# AE402FA0D5597BE0_CM55_HE_View register map
Vendor: Alif Semiconductor; Series: E4; File version: 1.0
CPU: CM55 r1p0, selectable endian, MPU, FPU, double-precision FPU, DSP, VTOR, 8 interrupt priority bits, 1 SAU regions
Registers are 32-bit, read-write, reset 0x0 unless marked. A register's access mark holds for its fields unless they carry their own. Offsets are from the block's base; [hi:lo] are bit positions; {n}, {i} and the like mark numbered series; 'fields as' and 'values as' point back to an identical list.

## ISP (part 1 of 2)
Base 0x49046000
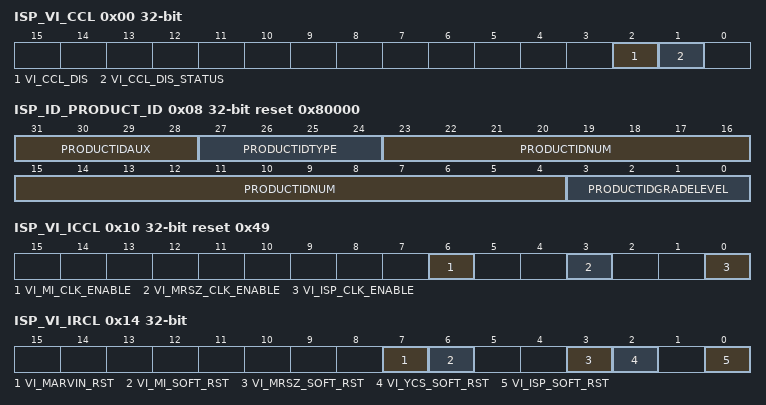
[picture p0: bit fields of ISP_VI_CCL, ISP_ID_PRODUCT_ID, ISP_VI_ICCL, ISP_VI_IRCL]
0x00 ISP_VI_CCL
  [2] VI_CCL_DIS — Clock Control Logic disable
    0=Processing/cfg-clocks for all sub modules enabled; 1=Processing/cfg-clocks for all sub modules disabled without access to ID and ISP_VI_CCL register
  [1] VI_CCL_DIS_STATUS — Status of ISP_vi_ccl[2] bit (copy of ISP_vi_ccl[2])
0x04 ISP_ID_CUSTOM_ID ro reset 0x50000091
  [31:0] ISP_ID_CUSTOM_ID — Shows Proejct ID, Each Project maps to a Unique ProjectID 0x83:
    128=Project-0; 129=Project-1; 130=Project-2
0x08 ISP_ID_PRODUCT_ID ro reset 0x80000
  [31:28] PRODUCTIDAUX — Product Aux
  [27:24] PRODUCTIDTYPE — Following is a Example for this 4bit field (GPU/VIP Using) , You can plan the values accordling to ISP 's Product RoadMap Product Type
    0=ISP Only; 1=DW Only; 2=VSE Only; 3=ISP + DW100; 4=ISP + DW100 + VSE; 5=ISP + DW200
  [23:4] PRODUCTIDNUM — Shows Product Number, Example: ISP8000L,ProductIDNum=0x08000 DW100,ProductIDNum=0x00100 DW200,ProductIDNum=0x00200
  [3:0] PRODUCTIDGRADELEVEL — Product GradeLevel
    0=None-no extra letter on the product name; 1=N (Nano); 2=L (Lite); 3=D,Dual; 4=N-D, Nano-Dual; 5=L-D, Lite-Dual
0x0C ISP_ID_CHIP_ID ro reset 0x8000
  [31:0] ISP_ID_CHIP_ID — Shows ChipID numbers ISPNano Series,ChipID=0x8000 ISP8000L Series,ChipID=0x8000 ISP8000 Series,ChipID=0x8000 DW100,ChipID=0x0100 DW200,ChipID=0x0200
0x10 ISP_VI_ICCL reset 0x49
  [all] fields
    0=Power safe; 1=Processing mode
  [6] VI_MI_CLK_ENABLE — Memory interface clock enable
  [3] VI_MRSZ_CLK_ENABLE — main resize clock enable
  [0] VI_ISP_CLK_ENABLE — ISP processing clock enable
0x14 ISP_VI_IRCL
  [all] fields
    0=Processing mode; 1=Reset state
  [7] VI_MARVIN_RST — Hardware reset of entire image signal processor
  [6] VI_MI_SOFT_RST — Memory interface software reset
  [3] VI_MRSZ_SOFT_RST — Main-picture resize software reset
  [2] VI_YCS_SOFT_RST — Y/C splitter software reset
  [0] VI_ISP_SOFT_RST — ISP software reset
0x20 ISP_ID_ECO_ID ro
  [31:0] ISP_ID_ECO_ID — Formal release is 0x0 The 1st ECO release is 0x1 The 2nd ECO release is 0x2
0x24 ISP_ID_CHIP_REVISION ro reset 0x5000
  [31:0] ISP_ID_CHIP_REVISION — Shows Tag Number Example: Tag=isp8000_1_2_1_rc3z Then,ChipRevision=0x0000_1213
0x28 ISP_ID_PATCH_REVISION ro reset 0x7
  [31:0] ISP_ID_PATCH_REVISION — Shows the last letter of a Tag Example: Tag=isp8000_1_2_1_rc3z Then,PatchRevision=8'd26 'a' map to 8'd1 'b' map to 8'd2 'z' map to 8'd26
0x2C ISP_ID_CHIP_DATE ro
  [31:0] ISP_ID_CHIP_DATE — Shows Date Value,such as 32'h20191120
0x30 ISP_ID_CHIP_TIME ro reset 0x1800
  [31:0] ISP_ID_CHIP_TIME — Shows Time Value,such as 32'h18365500
0x34 ISP_VI_ID_RSV0 ro reset 0xA100
  [31:0] MARVIN_ID_RSV0 — reserved id
0x38 ISP_VI_ID_RSV1 ro reset 0xA1
  [31:0] MARVIN_ID_RSV1 — reserved id
0x3C ISP_VI_ID_RSV2 ro reset 0xA2
  [31:0] MARVIN_ID_RSV2 — reserved id
0x40 ISP_VI_ID_RSV3 ro reset 0xA3
  [31:0] MARVIN_ID_RSV3 — reserved id
0x44 ISP_VI_ID_RSV4 ro reset 0xA4
  [31:0] MARVIN_ID_RSV4 — reserved id
0x48 ISP_VI_ID_RSV5 ro reset 0xA5
  [31:0] MARVIN_ID_RSV5 — reserved id
0x4C ISP_VI_ID_RSV6 ro reset 0xA6
  [31:0] MARVIN_ID_RSV6 — reserved id
0x50 ISP_VI_ID_RSV7 ro reset 0xA7
  [31:0] MARVIN_ID_RSV7 — reserved id
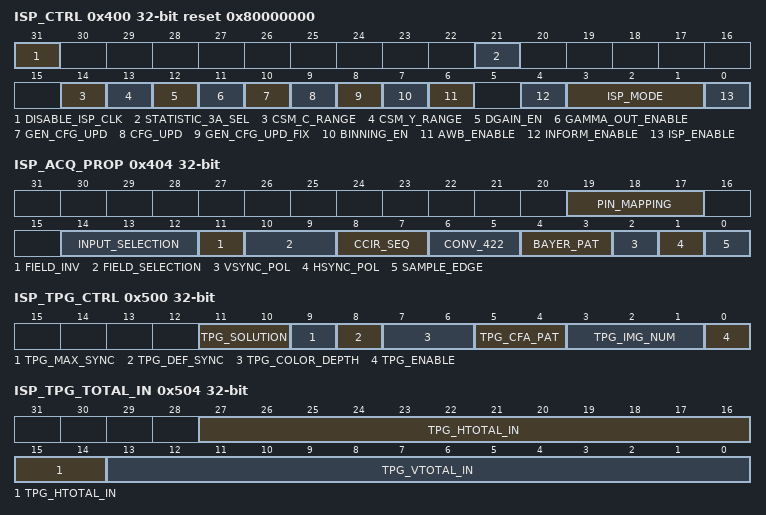
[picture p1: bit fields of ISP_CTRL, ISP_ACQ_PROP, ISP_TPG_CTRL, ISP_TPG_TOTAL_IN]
0x400 ISP_CTRL reset 0x80000000
  [31] DISABLE_ISP_CLK
    1=Enable ISP clock of SRAM. 0:disable isp clock of sram
  [21] STATISTIC_3A_SEL
    1=Select demosaic output 0: Select cc output
  [14] CSM_C_RANGE — Color Space Matrix chrominance clipping range for ISP output Numbers in brackets are for 8 bit resolution. This bit also configures the YCbCr sequence align block accordingly.
    0=CbCr range 64..960 (16..240) according to ITU-R BT.601 standard; 1=Full UV range 0..1023 (0..255)
  [13] CSM_Y_RANGE — Color Space Matrix luminance clipping range for ISP output Numbers in brackets are for 8 bit resolution. This bit also configures the YCbCr sequence align block accordingly.
    0=Y range 64..940 (16..235) according to ITU-R BT.601 standard; 1=Full Y range 0..1023 (0..255)
  [12] DGAIN_EN — digital gain enable
  [11] GAMMA_OUT_ENABLE — Gamma ON/OFF
  [10] GEN_CFG_UPD
    1=Generate frame synchronous configuration signal at the output of ISP for shadow registers of the following processing modules, write only
  [9] CFG_UPD
    1=Immediately configure (update) shadow registers, write only
  [8] GEN_CFG_UPD_FIX
    1=Make gen_cfg_upd a level signal, effect since then; 0=Gen_cfg_upd is a pulse signal, only effect for current frame
  [7] BINNING_EN — binning enable
  [6] AWB_ENABLE — Auto white balance ON/OFF
  [4] INFORM_ENABLE — input formatter The ISP input formatter is enabled or disabled by this bit immediately, But always starts or stops acquisition frame synchronously.
    0=Disabled; 1=Enabled
  [3:1] ISP_MODE — 000 - RAW picture with BT.601 sync (ISP bypass) 001 - ITU-R BT.656 (YUV with embedded sync) 010 - ITU-R BT.601 (YUV input with H and Vsync signals) 011 - Bayer RGB processing with H and Vsync signals 100 - data mode (ISP bypass, sync signals interpreted as data enable) 101 - Bayer RGB processing with BT.656 synchronization 110 - RAW picture with ITU-R BT.656 synchronization (ISP bypass) 111 - monochrome Side effect: If RAW, BT.601, BT.656, or data mode is selected, the clock of the ISP SRAMs (ISP line buffer, Lens Shading, Bad Pixel) is switched off. Only in Bayer RGB mode the clock to the SRAMs is enabled. This further reduces power consumption.
  [0] ISP_ENABLE — ISP data output Controls output formatter frame synchronously, if isp_gen_cfg_upd is Used to activate this bit. For immediate update isp_cfg_upd must be used.
    0=Disabled; 1=Enabled
0x404 ISP_ACQ_PROP
  [19:17] PIN_MAPPING — Bit mapping from LSB to MSB: 000 - normal 12-bit external Interface 001 - mapping Low 10 bit to High 10 bits, append 2 zeroes as LSBs 010 - mapping Low 8 bit to High 8 bits, append 4 zeroes as LSBs 011 - mapping Middle 8 bit to High 8 bits, append 4 zeroes as LSBs 100...111 - Reserved (from March 2018)
  [14:12] INPUT_SELECTION — 12bit/10bit/8bit input select modes 000- 12Bit external Interface 001- 10Bit Interface, append 2 zeroes as LSBs 010- 10Bit Interface, append 2 MSBs as LSBs 011- 8Bit Interface, append 4 zeroes as LSBs 100- 8Bit Interface, append 4 MSBs as LSBs 101...111 reserved
  [11] FIELD_INV
    0=Do not swap odd and even fields; 1=Swap odd and even fields
  [10:9] FIELD_SELECTION — 00- sample all fields (don't care about fields) 01- sample only even fields 10- sample only odd fields 11- reserved
  [8:7] CCIR_SEQ — 00- YCbYCr 01- YCrYCb 10- CbYCrY 11- CrYCbY
  [6:5] CONV_422 — 00- cosited color subsampling Y0Cb0Cr0 - Y1 01- interleaved color subsampling Y0Cb0 - Y1Cr1 (not recommended) 10- non-cosited color subsampling Y0Cb(0+1)/2 - Y1Cr(0+1)/2 11- reserved
  [4:3] BAYER_PAT — Color components from sensor, starting with top left position in sampled frame (reprogram with ISP_ACQ_H_OFFS, ISP_ACQ_V_OFFS) 00- first line: RGRG..., second line: GBGB..., etc. 01- first line: GRGR..., second line: BGBG..., etc. 10- first line: GBGB..., second line: RGRG..., etc. 11- first line: BGBG..., second line: GRGR..., etc. This configuration applies for the black level area after cropping by the input formatter.
  [2] VSYNC_POL — Vertical sync polarity
    0=High active; 1=Low active
  [1] HSYNC_POL — Horizontal sync polarity
    0=High active; 1=Low active
  [0] SAMPLE_EDGE — 0- negative edge sampling 1- positive edge sampling
0x408 ISP_ACQ_H_OFFS
  [14:0] ACQ_H_OFFS — Horizontal sample offset in 8-bit samples (YUV: 4 samples = 2 pixels)
0x40C ISP_ACQ_V_OFFS
  [13:0] ACQ_V_OFFS — Vertical sample offset in lines
0x410 ISP_ACQ_H_SIZE reset 0x1000
  [14:0] ACQ_H_SIZE — Horizontal sample size in 12-bit samples YUV input: 2 samples = 1 pixel, else 1 sample = 1 pixel So in YUV mode ACQ_H_SIZE must be twice as large as horizontal image size. Horizontal image size must always be even except in raw picture mode if an odd size is programmed, the value will be truncated to an even size.
0x414 ISP_ACQ_V_SIZE reset 0xC00
  [13:0] ACQ_V_SIZE — Vertical sample size in lines
0x500 ISP_TPG_CTRL
  [11:10] TPG_SOLUTION
    0=Val_0b00 (1080P (1920x1080)); 1=Val_0b01 (720P (1280x720)); 2=Val_0b10 (4K (3840x2160)); 3=Val_0b11 (User defined resolution and timing)
  [9] TPG_MAX_SYNC — Set to 1 to use VS/VDE and HS/HDE same behavior
  [8] TPG_DEF_SYNC — Set to 1 to select the default sync output
  [7:6] TPG_COLOR_DEPTH — Test Pattern Color Depth
    0=Val_0b00 (8-bit); 1=Val_0b01 (10-bit); 2=Val_0b10 (12-bit (pix_width))
  [5:4] TPG_CFA_PAT — Bayer pattern:
    0=Val_0b00 (RGGB); 1=Val_0b01 (GRBG); 2=Val_0b10 (GBRB); 3=Val_0b11 (BGGR)
  [3:1] TPG_IMG_NUM — Test Pattern Generator Image index Others: Reserved
    0=Val_0b000 (3x3 color block); 1=Val_0b001 (Color bar); 2=Val_0b010 (Gray Bar); 3=Val_0b011 (Highlighted grid); 4=Val_0b100 (Random Generator)
  [0] TPG_ENABLE — Enable/Disable Test Pattern Generator
    0=Disable the TPG; 1=Enable the TPG
0x504 ISP_TPG_TOTAL_IN
  [27:14] TPG_HTOTAL_IN — The total clock of vertical
  [13:0] TPG_VTOTAL_IN — The total clock of horizontal
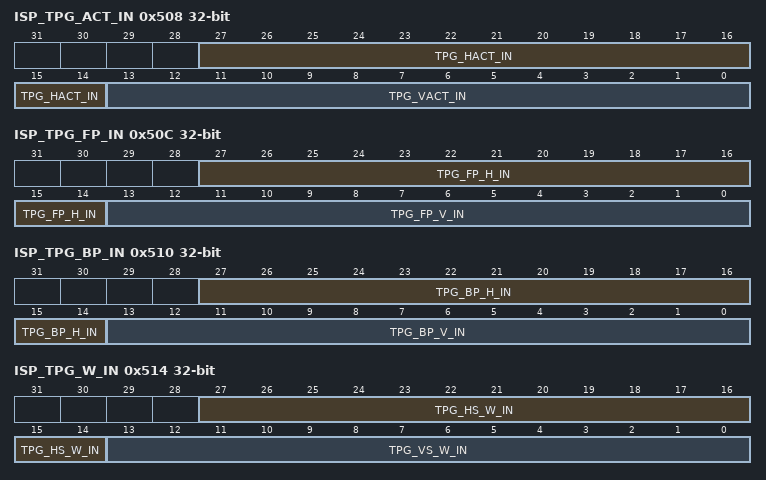
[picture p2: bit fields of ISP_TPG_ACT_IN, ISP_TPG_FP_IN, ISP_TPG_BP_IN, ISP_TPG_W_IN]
0x508 ISP_TPG_ACT_IN
  [27:14] TPG_HACT_IN — The total clock of horizontal
  [13:0] TPG_VACT_IN — The available clock of vertical
0x50C ISP_TPG_FP_IN
  [27:14] TPG_FP_H_IN — The first valid of hs
  [13:0] TPG_FP_V_IN — The first valid of vs
0x510 ISP_TPG_BP_IN
  [27:14] TPG_BP_H_IN — The distance between positive edge of vs with positive edge of hde
  [13:0] TPG_BP_V_IN — The distance between positive edge of vs with positive edge of vde
0x514 ISP_TPG_W_IN
  [27:14] TPG_HS_W_IN — Available clk of hs
  [13:0] TPG_VS_W_IN — Available clk of vs
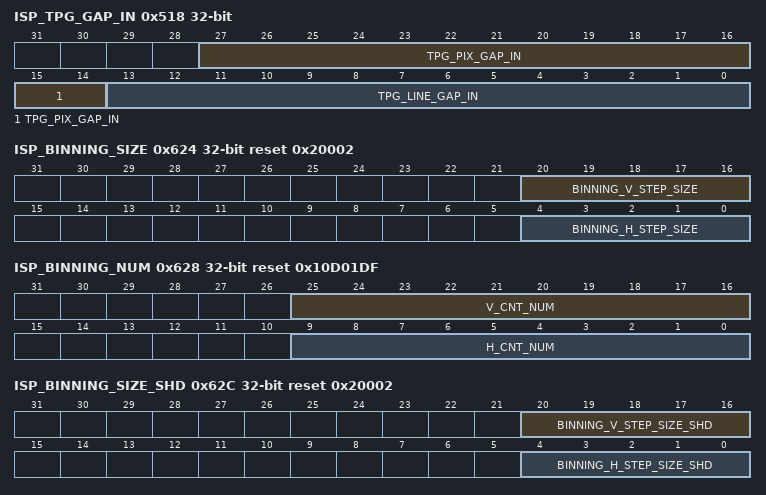
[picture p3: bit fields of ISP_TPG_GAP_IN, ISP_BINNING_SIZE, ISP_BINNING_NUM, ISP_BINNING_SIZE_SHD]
0x518 ISP_TPG_GAP_IN
  [27:14] TPG_PIX_GAP_IN — The width of sub_picture
  [13:0] TPG_LINE_GAP_IN — The height of sub_picture
0x51C ISP_TPG_GAP_STD_IN
  [13:0] TPG_PIX_GAP_STD_IN — The gap of sub_picture
0x520 ISP_TPG_RANDOM_SEED
  [31:0] TPG_RANDOM_SEED — Random seed
0x524 ISP_TPG_FRAME_NUM
  [15:0] TPG_FRAME_NUM — Other: when the frame_cnt &lt = frame_num, the output is valid
    0=all of the frame output is valid
0x600 ISP_FRAME_RATE
  [5:0] FRAME_RATE — Frame rate: N: 1/(N+1) of the original frame rate N: 1/(N=1) of the original frame rate
    0=Original frame rate; {v}=1/{v+1} of the original frame rate (v=1..6)
0x604 ISP_OUT_H_OFFS
  [13:0] OUT_H_OFFS — Horizontal pic offset in lines
0x608 ISP_OUT_V_OFFS
  [13:0] OUT_V_OFFS — Vertical pic offset in lines
0x60C ISP_OUT_H_SIZE reset 0x280
  [14:0] OUT_H_SIZE — Horizontal picture size in pixel if ISP_MODE is set to: 001-(ITU-R BT.656 YUV), 010-( ITU-R BT.601 YUV), 011-( ITU-R BT.601 Bayer RGB), 101-( ITU-R BT.656 Bayer RGB) Only even numbers are accepted, because complete quadruples of YUYV(YCbYCr) are needed for the 422 output. If an odd size is programmed, the value will be truncated to an even size.
0x610 ISP_OUT_V_SIZE reset 0x1E0
  [13:0] OUT_V_SIZE — Vertical picture size in lines
0x614 ISP_OUT_H_OFFS_SHD ro
  [13:0] OUT_H_OFFS_SHD — Current horizontal picture offset in lines
0x618 ISP_OUT_V_OFFS_SHD ro
  [13:0] OUT_V_OFFS_SHD — Current vertical picture offset in lines
0x61C ISP_OUT_H_SIZE_SHD ro
  [14:0] OUT_H_SIZE_SHD — Current horizontal picture size in pixels.
0x620 ISP_OUT_V_SIZE_SHD ro
  [13:0] OUT_V_SIZE_SHD — Current vertical picture size in lines.
0x624 ISP_BINNING_SIZE reset 0x20002
  [20:16] BINNING_V_STEP_SIZE — vertical step size ,if(binning_en) value&gt =1 and must be even
  [4:0] BINNING_H_STEP_SIZE — Horizontal step size ,if(binning_en) value&gt =1 and must be even
0x628 ISP_BINNING_NUM reset 0x10D01DF
  [25:16] V_CNT_NUM — vertical counter num accodring to vsize and v_step_size ,equal to ceil[vsize/(v_step_size*2)]-1
  [9:0] H_CNT_NUM — horizontal counter num accodring to hsize and h_step_size,ceil[hsize/(h_step_size*2)]-1
0x62C ISP_BINNING_SIZE_SHD ro reset 0x20002
  [20:16] BINNING_V_STEP_SIZE_SHD — vertical step size ,if(binning_en) value&gt =1 and must be even
  [4:0] BINNING_H_STEP_SIZE_SHD — Horizontal step size ,if(binning_en) value&gt =1 and must be even
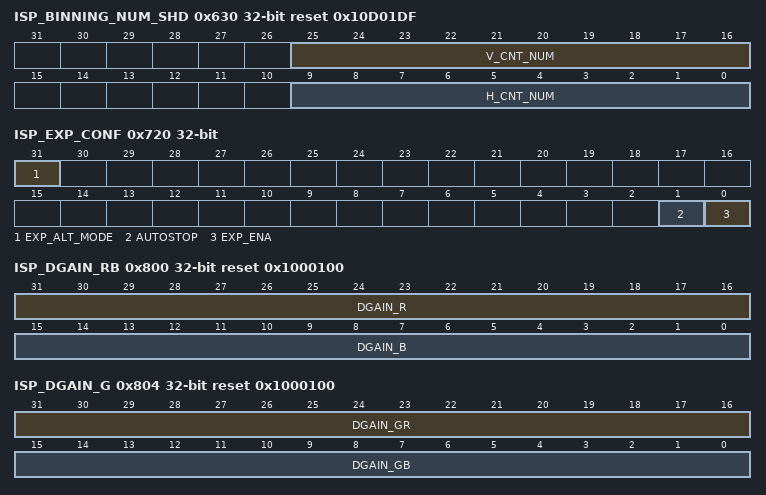
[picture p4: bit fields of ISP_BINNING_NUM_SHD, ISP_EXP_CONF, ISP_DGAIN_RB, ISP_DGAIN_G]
0x630 ISP_BINNING_NUM_SHD ro reset 0x10D01DF
  fields as ISP_BINNING_NUM
0x700 ISP_BLS_CTRL
  [0] BLS_EN
    1=Black level subtraction is enabled; 0=Bypass the black level processing
0x704 ISP_BLS_A_FIXED
  [12:0] BLS_A_FIXED — Fixed black level for A pixels-signed, two's complement Valid range from -4096 to +4095, A positive value will be subtracted from the pixel values
0x708 ISP_BLS_B_FIXED
  [12:0] BLS_B_FIXED — Fixed black level for B pixels-signed, two's complement Valid range from -4096 to +4095, A positive value will be subtracted from the pixel values
0x70C ISP_BLS_C_FIXED
  [12:0] BLS_C_FIXED — Fixed black level for C pixels-signed, two's complement Valid range from -4096 to +4095, A positive value will be subtracted from the pixel values
0x710 ISP_BLS_D_FIXED
  [12:0] BLS_D_FIXED — Fixed black level for D pixels-signed, two's complement Valid range from -4096 to +4095, A positive value will be subtracted from the pixel values
0x720 ISP_EXP_CONF
  [31] EXP_ALT_MODE
    0=Luminance calculation according to Y=16+0.25R+0.5G+0.1094B; 1=Luminance calculation according to Y=(R+G+B) x 0.332
  [1] AUTOSTOP
    0=Continuous measurement; 1=Stop measuring after a complete frame
  [0] EXP_ENA
    1=Start measuring a frame. If autostop is set to 1, the exposure block will reset this bit and halt after completing one frame.
0x724 ISP_EXP_H_OFFSET
  [12:0] EXP_H_OFFSET — Horizontal offset of first block in pixels.
0x728 ISP_EXP_V_OFFSET
  [12:0] EXP_V_OFFSET — Vertical offset of first block in pixels.
0x72C ISP_EXP_H_SIZE
  [10:0] EXP_H_SIZE — Horizontal size of one block in pixels.
0x730 ISP_EXP_V_SIZE
  [10:0] EXP_V_SIZE — Vertical size of one block in pixels (must be a multiple of 2). Note: The vertical size must be set in a way that after the last measurement window, At least two lines of the image will follow. I
{0x734+0x14*i} ISP_EXP_MEAN_{i:02} ro (i=0..4)
  [7:0] EXP_MEAN_{i:02} — Mean luminance value of block {i:02} (x,y)
{0x670+0x14*i} ISP_EXP_MEAN_{i} ro (i=10..14)
  [7:0] EXP_MEAN_{i} — Mean luminance value of block {i} (x,y)
{0x5AC+0x14*i} ISP_EXP_MEAN_{i} ro (i=20..24)
  [7:0] EXP_MEAN_{i} — Mean luminance value of block {i} (x,y)
{0x4E8+0x14*i} ISP_EXP_MEAN_{i} ro (i=30..34)
  [7:0] EXP_MEAN_{i} — Mean luminance value of block {i} (x,y)
{0x424+0x14*i} ISP_EXP_MEAN_{i} ro (i=40..44)
  [7:0] EXP_MEAN_{i} — Mean luminance value of block {i} (x,y)
0x800 ISP_DGAIN_RB reset 0x1000100
  [31:16] DGAIN_R — digital gain of red channel
  [15:0] DGAIN_B — digital gain of blue channel
0x804 ISP_DGAIN_G reset 0x1000100
  [31:16] DGAIN_GR — digital gain of red line green channel
  [15:0] DGAIN_GB — digital gain of blue line green channel
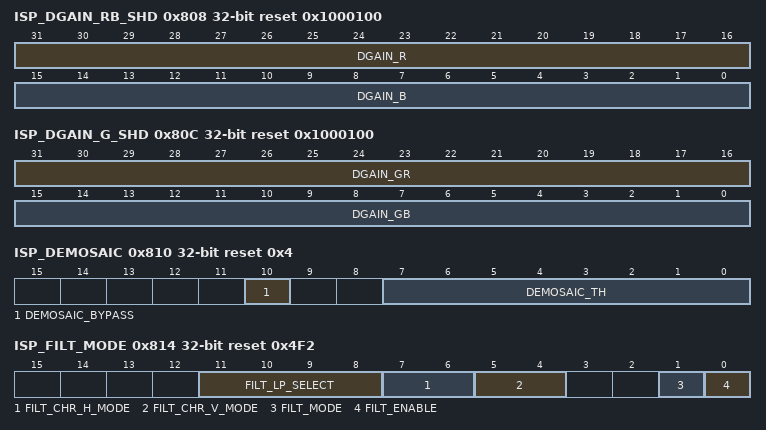
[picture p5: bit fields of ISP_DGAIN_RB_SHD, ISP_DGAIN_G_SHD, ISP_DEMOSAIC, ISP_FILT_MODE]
0x808 ISP_DGAIN_RB_SHD ro reset 0x1000100
  fields as ISP_DGAIN_RB
0x80C ISP_DGAIN_G_SHD ro reset 0x1000100
  fields as ISP_DGAIN_G
0x810 ISP_DEMOSAIC reset 0x4
  [10] DEMOSAIC_BYPASS — White input data
    0=Normal operation for RGB Bayer Pattern input; 1=Demosaicing bypass for Black&amp
  [7:0] DEMOSAIC_TH — Threshold for Bayer demosaicing texture detection. This value shifted left 4bit is compared with the difference of the vertical and horizontal 12Bit wide texture indicators, to decide if the vertical or horizontal texture flag must be set.
    0=Maximum edge sensitivity; 255=no texture detection
0x814 ISP_FILT_MODE reset 0x4F2
  [11:8] FILT_LP_SELECT — Green filter stage 1 select (Valid range: 0x0...0x8):
    0=Maximum blurring . . .; 4=Default; 7=minimum blurring; 8=filter stage1 bypass
  [7:6] FILT_CHR_H_MODE — Chroma filter horizontal mode:
    0=Val_0b00 (Horizontal chroma filter bypass); 1=Val_0b01 (Horizontal chroma filter 1 static mask = [10 12 10]); 2=Val_0b10 (Horizontal chroma filter 2 (dynamic blur1)); 3=Val_0b11 (Horizontal chroma filter 3 (dynamic blur2) (Default))
  [5:4] FILT_CHR_V_MODE — Chroma filter vertical mode:
    0=Val_0b00 (Vertical chroma filter bypass); 1=Val_0b01 (Vertical chroma filter 1 static [8 16 8]); 2=Val_0b10 (Vertical chroma filter 2 static [10 12 10]); 3=Val_0b11 (Vertical chroma filter 3 static [12 8 12] (Default))
  [1] FILT_MODE
    0=Green filter static mode (active filter factor = FILT_FAC_MID); 1=Dynamic noise reduction/sharpen (Default)
  [0] FILT_ENABLE
    1=Enable filter; 0=Bypass filter (Default)
0x818 ISP_FILT_THRES_BL0 reset 0xD
  [9:0] FILT_THRES_BL0 — If filt_thresh_bl1 &lt sum_grad &lt filt_thresh_bl0 then filt_fac_bl0 is selected Note: sum_grad is calculated by the texture detection unit as the sum of horizontal and vertical gradients
0x81C ISP_FILT_THRES_BL1 reset 0x5
  [9:0] FILT_THRES_BL1 — If sum_grad &lt filt_thresh_bl1 then filt_fac_bl1 is selected Note: sum_grad is calculated by the texture detection unit as the sum of horizontal and vertical gradients
0x820 ISP_FILT_THRES_SH0 reset 0x1A
  [9:0] FILT_THRES_SH0 — If filt_thresh_sh1 &lt sum_grad &lt filt_thresh_sh0 then filt_fac_bl0 is selected Note: sum_grad is calculated by the texture detection unit as the sum of horizontal and vertical gradients
0x824 ISP_FILT_THRES_SH1 reset 0x2C
  [9:0] FILT_THRES_SH1 — If sum_grad &lt filt_thresh_sh1 then filt_fac_bl1 is selected Note: sum_grad is calculated by the texture detection unit as the sum of horizontal and vertical gradients
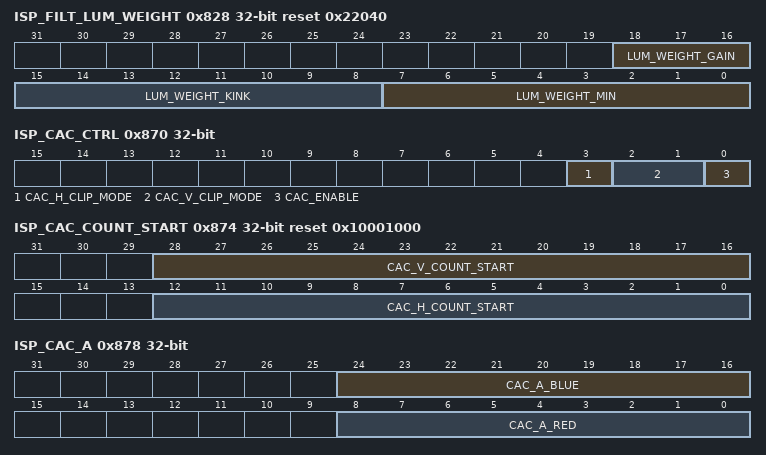
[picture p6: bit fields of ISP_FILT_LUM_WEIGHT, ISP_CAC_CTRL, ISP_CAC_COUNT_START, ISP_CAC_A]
0x828 ISP_FILT_LUM_WEIGHT reset 0x22040
  [18:16] LUM_WEIGHT_GAIN — Gain select of luminance weight function
  [15:8] LUM_WEIGHT_KINK — Kink position of luminance weight function
  [7:0] LUM_WEIGHT_MIN — Minimum value of luminance weight function
0x82C ISP_FILT_FAC_SH1 reset 0x10
  [5:0] FILT_FAC_SH1 — Filter factor for sharp1 level
0x830 ISP_FILT_FAC_SH0 reset 0xC
  [5:0] FILT_FAC_SH0 — Filter factor for sharp0 level
0x834 ISP_FILT_FAC_MID reset 0xA
  [5:0] FILT_FAC_MID — Filter factor for mid level and for static filter mode
0x838 ISP_FILT_FAC_BL0 reset 0x6
  [5:0] FILT_FAC_BL0 — Filter factor for blur 0 level
0x83C ISP_FILT_FAC_BL1 reset 0x2
  [5:0] FILT_FAC_BL1 — Filter factor for blur 1 level (max blur)
0x870 ISP_CAC_CTRL
  [3] CAC_H_CLIP_MODE — Defines the maximum red/blue pixel shift in horizontal direction At pixel positions, that require a larger displacement, the maximum shift value is used instead (vector clipping)
    0=Set horizontal vector clipping to +/-4 pixel displacement (Default); 1=Set horizontal vector clipping to +/-4 or +/-5 pixel displacement depending on pixel position inside the Bayer raster (dynamic switching between +/-4 and +/-5)
  [2:1] CAC_V_CLIP_MODE — Defines the maximum red/blue pixel shift in vertical direction fix filter_enable (Default) dynamic filter_enable for chroma low pass filter
    0=Val_0b00 (Set vertical vector clipping to +/-2 pixel); 1=Val_0b01 (Set vertical vector clipping to +/-3 pixel); 2=Val_0b10 (Set vertical vector clipping +/-3 or +/-4 pixel displacement depending on pixel position inside the Bayer raster (dynamic switching between +/-3 and +/-4))
  [0] CAC_ENABLE
    0=Chromatic aberration correction off; 1=Chromatic aberration correction on
0x874 ISP_CAC_COUNT_START reset 0x10001000
  [28:16] CAC_V_COUNT_START — 12 bit v_count preload value (range 4095 ... 1) of the vertical CAC line counter. Before frame start v_count has to be preloaded with (v_size/2 + v_center_offset), with v_size the image height and v_center_offset the vertical distance between image center and optical center. After frame start the v_count decrements with every line until a value of zero is reached for the line in the optical center. Than the v_sign bit toggles and the v_counter decrements with every line until end of frame.
  [12:0] CAC_H_COUNT_START — 12 bit h_count preload value (range 4095 .. 1) of the horizontal CAC pixel counter. Before line start h_count has to be preloaded with (h_size/2 + h_center_offset), with h_size the image width and h_center_offset the horizontal distance between image center and optical center. After line start the h_count decrements with every pixel until a value of zero is reached for the column in the optical center. Than the h_sign bit toggles and the h_counter increments with every pixel until end of line.
0x878 ISP_CAC_A
  [24:16] CAC_A_BLUE — Parameter A_Blue for radial blue shift calculation, according to (A_Blue * r + B_Blue * r^2 + C_Blue * r^3). It is a 9 bit twos complement integer with 4 fractional digits value and value range from -16 up to 15.9375.
  [8:0] CAC_A_RED — Parameter A_Red for radial red shift calculation, according to (A_Red * r + B_Red * r^2 + C_Red * r^3). It is a 9 bit twos complement integer with 4 fractional digits value and value range from -16 up to 15.9375.
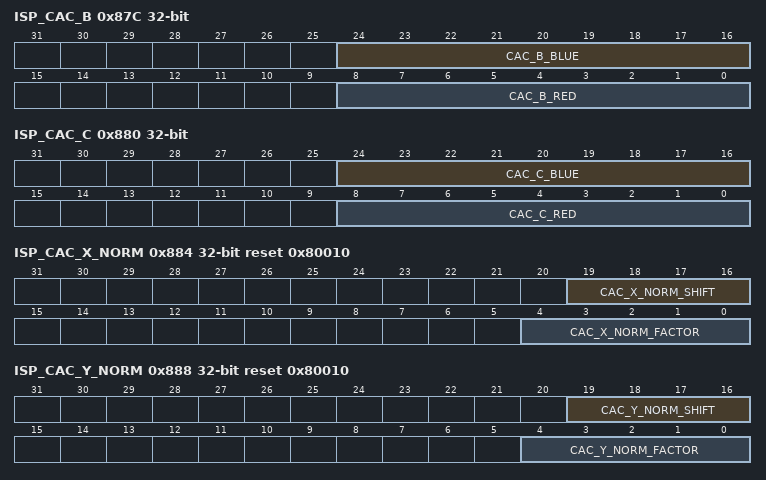
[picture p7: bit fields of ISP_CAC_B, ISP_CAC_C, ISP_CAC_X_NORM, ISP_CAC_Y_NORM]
0x87C ISP_CAC_B
  [24:16] CAC_B_BLUE — Parameter B_Blue for radial blue shift calculation, according to (A_Blue * r + B_Blue * r^2 + C_Blue * r^3). It is a 9 bit twos complement integer with 4 fractional digits value and value range from -16 up to 15.9375.
  [8:0] CAC_B_RED — Parameter B_Red for radial red shift calculation, according to (A_Red * r + B_Red * r^2 + C_Red * r^3). It is a 9 bit twos complement integer with 4 fractional digits value and value range from -16 up to 15.9375.
0x880 ISP_CAC_C
  [24:16] CAC_C_BLUE — Parameter C_Blue for radial blue shift calculation, according to (A_Blue * r + B_Blue * r^2 + C_Blue * r^3). It is a 9 bit twos complement integer with 4 fractional digits value and value range from -16 up to 15.9375.
  [8:0] CAC_C_RED — Parameter C_Red for radial red shift calculation, according to (A_Red * r + B_Red * r^2 + C_Red * r^3). It is a 9 bit twos complement integer with 4 fractional digits value and value range from -16 up to 15.9375.
0x884 ISP_CAC_X_NORM reset 0x80010
  [19:16] CAC_X_NORM_SHIFT — Horizontal normalization shift parameter x_ns (3 bit unsigned integer) in equation x_d[7:0] = (((h_count &lt &lt 4) &gt &gt x_ns) * x_normfactor) &gt &gt 5
  [4:0] CAC_X_NORM_FACTOR — Horizontal scaling factor x_normfactor (5 bit unsigned integer) range 0 .. 31 in equation x_d[7:0] = (((h_count &lt &lt 4) &gt &gt x_ns) * x_normfactor) &gt &gt 5
0x888 ISP_CAC_Y_NORM reset 0x80010
  [19:16] CAC_Y_NORM_SHIFT — Vertical normalization shift parameter y_ns (3 bit unsigned integer) in equation y_d[7:0] = (((v_count &lt &lt 4) &gt &gt y_ns) * y_normfactor) &gt &gt 5
  [4:0] CAC_Y_NORM_FACTOR — Vertical scaling factor y_normfactor (5 bit unsigned integer) range 0 .. 31 in equation y_d[7:0] = (((v_count &lt &lt 4) &gt &gt y_ns) * y_normfactor) &gt &gt 5
0x900 ISP_GAMMA_OUT_MODE
  [0] EQU_SEGM — segmentation from 0 to 4095: 64 64 64 64 128 128 128 128 256 256 256 512 512 512 512 512
    0=Logarithmic like segmentation of gamma curve (default after reset); 1=Equidistant segmentation (all 16 segments are 256)
0x904 ISP_GAMMA_OUT_Y_0
  [9:0] GAMMA_OUT_Y0 — Gamma_out curve point definition y-axis (output) for all color components (red,green,blue) RESTRICTION: The difference between two Y_n (dy = Y_n - Y_n-1) is restricted to +511/-512 (10 bit signed).
0x908 ISP_GAMMA_OUT_Y_1 reset 0x49
  [9:0] GAMMA_OUT_Y1 — Gamma_out curve point definition y-axis (output) for all color components (red,green,blue) RESTRICTION: The difference between two Y_n (dy = Y_n - Y_n-1) is restricted to +511/-512 (10 bit signed).
0x90C ISP_GAMMA_OUT_Y_2 reset 0x89
  [9:0] GAMMA_OUT_Y2 — Gamma_out curve point definition y-axis (output) for all color components (red,green,blue) RESTRICTION: The difference between two Y_n (dy = Y_n - Y_n-1) is restricted to +511/-512 (10 bit signed).
0x910 ISP_GAMMA_OUT_Y_3 reset 0xB7
  [9:0] GAMMA_OUT_Y3 — Gamma_out curve point definition y-axis (output) for all color components (red,green,blue) RESTRICTION: The difference between two Y_n (dy = Y_n - Y_n-1) is restricted to +511/-512 (10 bit signed).
0x914 ISP_GAMMA_OUT_Y_4 reset 0xDF
  [9:0] GAMMA_OUT_Y4 — Gamma_out curve point definition y-axis (output) for all color components (red,green,blue) RESTRICTION: The difference between two Y_n (dy = Y_n - Y_n-1) is restricted to +511/-512 (10 bit signed).
0x918 ISP_GAMMA_OUT_Y_5 reset 0x11F
  [9:0] GAMMA_OUT_Y5 — Gamma_out curve point definition y-axis (output) for all color components (red,green,blue) RESTRICTION: The difference between two Y_n (dy = Y_n - Y_n-1) is restricted to +511/-512 (10 bit signed).
0x91C ISP_GAMMA_OUT_Y_6 reset 0x154
  [9:0] GAMMA_OUT_Y6 — Gamma_out curve point definition y-axis (output) for all color components (red,green,blue) RESTRICTION: The difference between two Y_n (dy = Y_n - Y_n-1) is restricted to +511/-512 (10 bit signed).
0x920 ISP_GAMMA_OUT_Y_7 reset 0x183
  [9:0] GAMMA_OUT_Y7 — Gamma_out curve point definition y-axis (output) for all color components (red,green,blue) RESTRICTION: The difference between two Y_n (dy = Y_n - Y_n-1) is restricted to +511/-512 (10 bit signed).
0x924 ISP_GAMMA_OUT_Y_8 reset 0x1AD
  [9:0] GAMMA_OUT_Y8 — Gamma_out curve point definition y-axis (output) for all color components (red,green,blue) RESTRICTION: The difference between two Y_n (dy = Y_n - Y_n-1) is restricted to +511/-512 (10 bit signed).
0x928 ISP_GAMMA_OUT_Y_9 reset 0x1F6
  [9:0] GAMMA_OUT_Y9 — Gamma_out curve point definition y-axis (output) for all color components (red,green,blue) RESTRICTION: The difference between two Y_n (dy = Y_n - Y_n-1) is restricted to +511/-512 (10 bit signed).
0x92C ISP_GAMMA_OUT_Y_10 reset 0x235
  [9:0] GAMMA_OUT_Y10 — Gamma_out curve point definition y-axis (output) for all color components (red,green,blue) RESTRICTION: The difference between two Y_n (dy = Y_n - Y_n-1) is restricted to +511/-512 (10 bit signed).
0x930 ISP_GAMMA_OUT_Y_11 reset 0x26F
  [9:0] GAMMA_OUT_Y11 — Gamma_out curve point definition y-axis (output) for all color components (red,green,blue) RESTRICTION: The difference between two Y_n (dy = Y_n - Y_n-1) is restricted to +511/-512 (10 bit signed).
0x934 ISP_GAMMA_OUT_Y_12 reset 0x2D3
  [9:0] GAMMA_OUT_Y12 — Gamma_out curve point definition y-axis (output) for all color components (red,green,blue) RESTRICTION: The difference between two Y_n (dy = Y_n - Y_n-1) is restricted to +511/-512 (10 bit signed).
0x938 ISP_GAMMA_OUT_Y_13 reset 0x32A
  [9:0] GAMMA_OUT_Y13 — Gamma_out curve point definition y-axis (output) for all color components (red,green,blue) RESTRICTION: The difference between two Y_n (dy = Y_n - Y_n-1) is restricted to +511/-512 (10 bit signed).
0x93C ISP_GAMMA_OUT_Y_14 reset 0x378
  [9:0] GAMMA_OUT_Y14 — Gamma_out curve point definition y-axis (output) for all color components (red,green,blue) RESTRICTION: The difference between two Y_n (dy = Y_n - Y_n-1) is restricted to +511/-512 (10 bit signed).
0x940 ISP_GAMMA_OUT_Y_15 reset 0x3BF
  [9:0] GAMMA_OUT_Y15 — Gamma_out curve point definition y-axis (output) for all color components (red,green,blue) RESTRICTION: The difference between two Y_n (dy = Y_n - Y_n-1) is restricted to +511/-512 (10 bit signed).
0x944 ISP_GAMMA_OUT_Y_16 reset 0x3FF
  [9:0] GAMMA_OUT_Y16 — Gamma_out curve point definition y-axis (output) for all color components (red,green,blue) RESTRICTION: The difference between two Y_n (dy = Y_n - Y_n-1) is restricted to +511/-512 (10 bit signed).
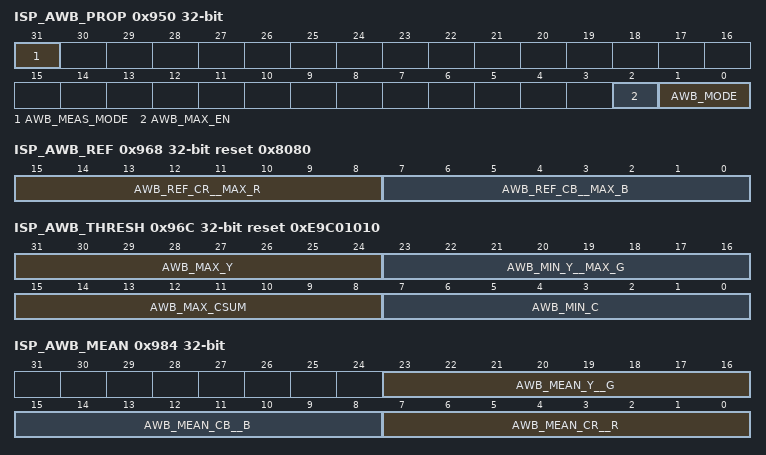
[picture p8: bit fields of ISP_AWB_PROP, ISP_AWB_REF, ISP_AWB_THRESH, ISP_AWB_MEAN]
0x950 ISP_AWB_PROP
  [31] AWB_MEAS_MODE
    1=RGB based measurement mode; 0=Near white discrimination mode using YCbCr color space
  [2] AWB_MAX_EN — Not valid in RGB measurement mode.
    0=Disable; 1=Enable
  [1:0] AWB_MODE — or RGB means (AWB_MEAS_MODE = 1)
    0=Val_0b00 (No measurement); 2=Val_0b10 (Measurement of YCbCr means (AWB_MEAS_MODE = 0))
0x954 ISP_AWB_H_OFFS
  [12:0] H_OFFS — Horizontal window offset in pixels
0x958 ISP_AWB_V_OFFS
  [12:0] V_OFFS — Vertical window offset in lines
0x95C ISP_AWB_H_SIZE
  [13:0] H_SIZE — Horizontal measurement of window size in pixels
0x960 ISP_AWB_V_SIZE
  [13:0] V_SIZE — Vertical measurement of window size in lines
0x964 ISP_AWB_FRAMES
  [2:0] AWB_FRAMES — Number of frames - 1 used for mean value calculation (a value of 0 means 1 frame a value of 7 means 8 frames)
0x968 ISP_AWB_REF reset 0x8080
  [15:8] AWB_REF_CR__MAX_R — Reference Cr value for AWB regulation target for AWB - maximum red value, if RGB measurement mode is selected
  [7:0] AWB_REF_CB__MAX_B — Reference Cb value for AWB regulation target for AWB - maximum red value, if RGB measurement mode is selected
0x96C ISP_AWB_THRESH reset 0xE9C01010
  [31:24] AWB_MAX_Y — Luminance maximum value, only consider pixels with luminance smaller than threshold for the White Balance measurement (must be enabled by register AWB_MODE bit AWB_MAX_EN). Not valid for RGB measurement mode.
  [23:16] AWB_MIN_Y__MAX_G — Luminance minimum value, only consider pixels with luminance greater than threshold for the White Balance measurement - Maximum green value, if RGB measurement mode is selected
  [15:8] AWB_MAX_CSUM — Chrominance sum maximum value, only consider pixels with Cb+Cr Smaller than threshold for White Balance measurements
  [7:0] AWB_MIN_C — Chrominance minimum value, only consider pixels with Cb/Cr each Greater than threshold value for White Balance measurements
0x980 ISP_AWB_WHITE_CNT ro
  [27:0] AWB_WHITE_CNT — White pixel count, number of 'white pixels' found during last measurement, I.e. pixels included in mean value calculation
0x984 ISP_AWB_MEAN ro
  [23:16] AWB_MEAN_Y__G — Mean value of Cb within window and frames- Mean value of blue, If RGB measurement mode is selected
  [15:8] AWB_MEAN_CB__B — Mean value of Cr within window and frames- Mean value of red, if RGB measurement mode is selected
  [7:0] AWB_MEAN_CR__R — Mean value of Y within window and frames- mean value of green, if RGB measurement mode is selected
